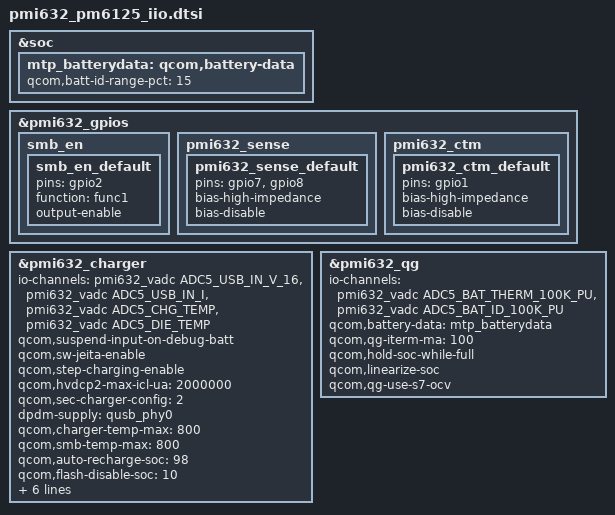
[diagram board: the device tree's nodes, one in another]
#include <dt-bindings/iio/qti_power_supply_iio.h>
#include <dt-bindings/pinctrl/qcom,pmic-gpio.h>
#include <dt-bindings/interrupt-controller/irq.h>
#include <dt-bindings/iio/qcom,spmi-vadc.h>
#include "pmi632.dtsi"
#include "pm6125.dtsi"

&soc {
	mtp_batterydata: qcom,battery-data {
		qcom,batt-id-range-pct = <15>;
		#include "qg-batterydata-alium-3600mah.dtsi"
	};
};

&pmi632_gpios {
	smb_en {
		smb_en_default: smb_en_default {
			pins = "gpio2";
			function = "func1";
			output-enable;
		};
	};

	pmi632_sense {
		/* GPIO 7 and 8 are external-sense pins for PMI632 */
		 pmi632_sense_default: pmi632_sense_default {
			pins = "gpio7", "gpio8";
			bias-high-impedance;    /* disable the GPIO */
			bias-disable;           /* no-pull */
		};
	};

	pmi632_ctm {
		/* Disable GPIO1 for h/w base mitigation */
		pmi632_ctm_default: pmi632_ctm_default {
			pins = "gpio1";
			bias-high-impedance;    /* disable the GPIO */
			bias-disable;           /* no-pull */
		};
	};
};

&pmi632_charger {
	status = "ok";
	#io-channel-cells = <1>;
	io-channels = <&pmi632_vadc ADC5_USB_IN_V_16>,
			<&pmi632_vadc ADC5_USB_IN_I>,
			<&pmi632_vadc ADC5_CHG_TEMP>,
			<&pmi632_vadc ADC5_DIE_TEMP>;
			<&pmi632_qg PSY_IIO_RESISTANCE_ID>,
			<&pmi632_qg PSY_IIO_VOLTAGE_NOW>,
			<&pmi632_qg PSY_IIO_TEMP>,
			<&pmi632_qg PSY_IIO_CAPACITY>,
			<&pmi632_qg PSY_IIO_VOLTAGE_OCV>,
			<&pmi632_qg PSY_IIO_VOLTAGE_AVG>,
			<&pmi632_qg PSY_IIO_DEBUG_BATTERY>,
			<&pmi632_qg PSY_IIO_REAL_CAPACITY>,
			<&pmi632_qg PSY_IIO_CC_SOC>,
			<&pmi632_qg PSY_IIO_CURRENT_NOW>,
			<&pmi632_qg PSY_IIO_VOLTAGE_MAX>,
			<&pmi632_qg PSY_IIO_CHARGE_FULL>,
			<&pmi632_qg PSY_IIO_CHARGE_COUNTER>,
			<&pmi632_qg PSY_IIO_CYCLE_COUNT>,
			<&pmi632_qg PSY_IIO_CHARGE_FULL_DESIGN>,
			<&pmi632_qg PSY_IIO_TIME_TO_FULL_NOW>,
	io-channel-names = "usb_in_voltage",
			   "usb_in_current",
			   "chg_temp",
			   "die_temp",
			   "resistance_id",
			   "voltage_now",
			   "temp",
			   "capacity",
			   "voltage_ocv",
			   "voltage_avg",
			   "debug_battery",
			   "real_capacity",
			   "cc_soc",
			   "current_now",
			   "voltage_max",
			   "charge_full",
			   "charge_counter",
			   "cycle_count",
			   "charge_full_design",
			   "time_to_full_now",
	qcom,battery-data = <&mtp_batterydata>;
	qcom,suspend-input-on-debug-batt;
	qcom,sw-jeita-enable;
	qcom,step-charging-enable;
	qcom,hvdcp2-max-icl-ua = <2000000>;
	/* SMB1355 only */
	qcom,sec-charger-config = <2>;
	dpdm-supply = <&qusb_phy0>;
	qcom,charger-temp-max = <800>;
	qcom,smb-temp-max = <800>;
	qcom,auto-recharge-soc = <98>;
	qcom,flash-disable-soc = <10>;
	qcom,hw-die-temp-mitigation;
	qcom,hw-connector-mitigation;
	qcom,connector-internal-pull-kohm = <100>;
	qcom,float-option = <1>;
	qcom,thermal-mitigation = <3000000 2500000
			2000000 1500000 1000000 500000>;
};

&pmi632_qg {
	status = "ok";
	#io-channel-cells = <1>;
	io-channels = <&pmi632_vadc ADC5_BAT_THERM_100K_PU>,
			<&pmi632_vadc ADC5_BAT_ID_100K_PU>;
			<&pmi632_charger PSY_IIO_INPUT_CURRENT_LIMITED>,
			<&pmi632_charger PSY_IIO_RECHARGE_SOC>,
			<&pmi632_charger PSY_IIO_FORCE_RECHARGE>,
			<&pmi632_charger PSY_IIO_CHARGE_DONE>,
	io-channel-names = "batt-therm",
			   "batt-id",
			   "input_current_limited",
			   "recharge_soc",
			   "force_recharge",
			   "charge_done",
			   "cp_charging_enabled";
	qcom,battery-data = <&mtp_batterydata>;
	qcom,qg-iterm-ma = <100>;
	qcom,hold-soc-while-full;
	qcom,linearize-soc;
	qcom,qg-use-s7-ocv;
};
